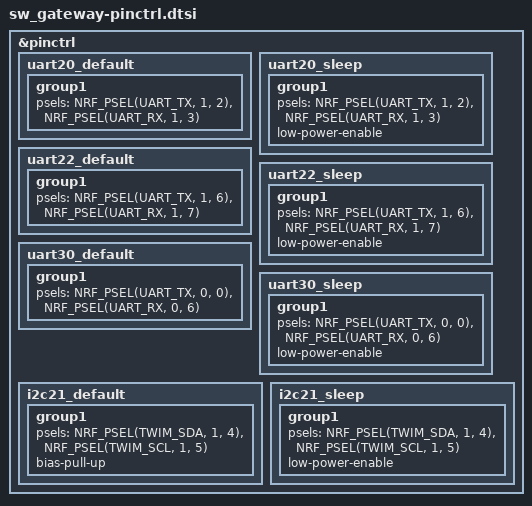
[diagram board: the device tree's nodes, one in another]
/*
 * Smart Wagon Gateway pin control.
 *
 * Every assignment here was checked against the netlist of
 * DOCS/Schematic/1.Main_Gateway_nrf54l15.PDF. Comms pins live here; the plain
 * control GPIOs (power switches, charger, GNSS/modem control) are named in
 * GATEWAY/src/board_pins.h and driven directly.
 *
 * SPDX-License-Identifier: Apache-2.0
 */

&pinctrl {
	/* Debug header D_TX / D_RX. These are the NFC pins, released to GPIO by
	 * the &uicr nfct-pins-as-gpios property in the board .dts. */
	uart20_default: uart20_default {
		group1 {
			psels = <NRF_PSEL(UART_TX, 1, 2)>,
				<NRF_PSEL(UART_RX, 1, 3)>;
		};
	};

	uart20_sleep: uart20_sleep {
		group1 {
			psels = <NRF_PSEL(UART_TX, 1, 2)>,
				<NRF_PSEL(UART_RX, 1, 3)>;
			low-power-enable;
		};
	};

	/*
	 * EC200U 4G modem, through the TXS0102.
	 *
	 * The schematic nets are named for the MODULE, not the nRF:
	 * UART_TX carries the EC200U's MAIN_TXD (pin 67, an output)
	 * and lands on nRF P1.07, so P1.07 is this side's RX. Taking
	 * the names at face value put TX on P1.07 - output driving
	 * output - and left our RX on the module's RXD input, where
	 * nothing drives but the translator's 10k pull-up. The board
	 * looked dead while the modem was up and transmitting.
	 */
	uart22_default: uart22_default {
		group1 {
			psels = <NRF_PSEL(UART_TX, 1, 6)>,
				<NRF_PSEL(UART_RX, 1, 7)>;
		};
	};

	uart22_sleep: uart22_sleep {
		group1 {
			psels = <NRF_PSEL(UART_TX, 1, 6)>,
				<NRF_PSEL(UART_RX, 1, 7)>;
			low-power-enable;
		};
	};

	/*
	 * LC29H GNSS. uart30 is the instance that reaches port 0.
	 *
	 * Same module-referenced naming as the modem above:
	 * UART_TX_LC is the LC29H's TXD (pin 20, an output) and
	 * reaches nRF P0.06, so P0.06 is our RX. NMEA was arriving on
	 * a pin configured as an output and being discarded.
	 */
	uart30_default: uart30_default {
		group1 {
			psels = <NRF_PSEL(UART_TX, 0, 0)>,
				<NRF_PSEL(UART_RX, 0, 6)>;
		};
	};

	uart30_sleep: uart30_sleep {
		group1 {
			psels = <NRF_PSEL(UART_TX, 0, 0)>,
				<NRF_PSEL(UART_RX, 0, 6)>;
			low-power-enable;
		};
	};

	/* BMA400 (0x14) + SHT40 (0x44) + BQ25798 (0x6B) share this bus.
	 * R4/R5 are the 4.7k pull-ups on VCC_AXI; bias-pull-up here is belt and
	 * braces for the window where that rail is settling. */
	i2c21_default: i2c21_default {
		group1 {
			psels = <NRF_PSEL(TWIM_SDA, 1, 4)>,
				<NRF_PSEL(TWIM_SCL, 1, 5)>;
			bias-pull-up;
		};
	};

	i2c21_sleep: i2c21_sleep {
		group1 {
			psels = <NRF_PSEL(TWIM_SDA, 1, 4)>,
				<NRF_PSEL(TWIM_SCL, 1, 5)>;
			low-power-enable;
		};
	};
};
